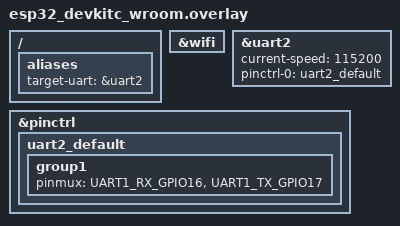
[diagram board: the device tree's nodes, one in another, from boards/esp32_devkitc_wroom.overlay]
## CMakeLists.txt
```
# Copyright (c) 2024 Common Ground Electronics
# SPDX-License-Identifier: Apache-2.0

cmake_minimum_required(VERSION 3.20.0)

find_package(Zephyr REQUIRED HINTS $ENV{ZEPHYR_BASE})
project(golioth-serial-logger)

target_sources(app PRIVATE src/main.c)
target_sources(app PRIVATE src/serial_listener.c)
target_sources(app PRIVATE src/logger.c)
```

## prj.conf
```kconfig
# Copyright (c) 2022-2023 Golioth, Inc.
# Copyright (c) 2024 Common Ground Electronics
# SPDX-License-Identifier: Apache-2.0

# Enable Golioth Firmware SDK
CONFIG_GOLIOTH_FIRMWARE_SDK=y

# Golioth services used in this app
CONFIG_GOLIOTH_FW_UPDATE=y
CONFIG_LOG_BACKEND_GOLIOTH=y

# Enable common sample library
CONFIG_GOLIOTH_SAMPLE_COMMON=y
CONFIG_GOLIOTH_SAMPLE_HARDCODED_CREDENTIALS=n

# Application
CONFIG_MAIN_STACK_SIZE=2048
CONFIG_SYSTEM_WORKQUEUE_STACK_SIZE=2048

# Flash memory (etc.) for firmware upgrade
CONFIG_FLASH=y
CONFIG_FLASH_MAP=y
CONFIG_NVS=y
CONFIG_STREAM_FLASH=y
CONFIG_IMG_MANAGER=y
CONFIG_IMG_ERASE_PROGRESSIVELY=y

# The rest of the runtime credentials config
CONFIG_SETTINGS=y
CONFIG_SETTINGS_RUNTIME=y
CONFIG_GOLIOTH_SAMPLE_PSK_SETTINGS=y
CONFIG_GOLIOTH_SAMPLE_SETTINGS_AUTOLOAD=y
CONFIG_GOLIOTH_SAMPLE_SETTINGS_SHELL=y

# Enable MCUboot
# CONFIG_BOOTLOADER_MCUBOOT=y

# Firmware version used in DFU process
CONFIG_MCUBOOT_IMGTOOL_SIGN_VERSION="0.1.0"
```

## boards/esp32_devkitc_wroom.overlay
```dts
/*
 * Copyright (c) 2024 Common Ground Electronics
 *
 * SPDX-License-Identifier: Apache-2.0
 */

/ {
	aliases {
		target-uart = &uart2;
	};
};

&wifi {
	status = "okay";
};

&uart2 {
	status = "okay";
	current-speed = <115200>;
	pinctrl-0 = <&uart2_default>;
	pinctrl-names = "default";
};

&pinctrl {
	uart2_default: uart2_default {
		group1 {
			pinmux = <UART1_RX_GPIO16>, <UART1_TX_GPIO17>;
		};
	};
};
```

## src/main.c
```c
/*
 * Copyright (c) 2024 Common Ground Electronics
 *
 * SPDX-License-Identifier: Apache-2.0
 */

#include <zephyr/kernel.h>
#include <zephyr/logging/log.h>
#include <golioth/client.h>
#include <samples/common/net_connect.h>
#include <samples/common/sample_credentials.h>

#include "serial_listener.h"
#include "logger.h"

LOG_MODULE_REGISTER(main, LOG_LEVEL_INF);

struct golioth_client *client;

static void on_client_event(struct golioth_client *client, enum golioth_client_event event,
			    void *arg)
{
	switch (event) {
	case GOLIOTH_CLIENT_EVENT_CONNECTED:
		LOG_INF("Golioth client connected");
		break;
	case GOLIOTH_CLIENT_EVENT_DISCONNECTED:
		LOG_INF("Golioth client disconnected");
		break;
	}
}

int main(void)
{
	int ret;
	char msg[LOG_MSG_SIZE];

	LOG_INF("Starting Golioth Serial Logger App");

	/* Initialize the serial listener */
	if (serial_listener_init()) {
		return 0;
	}

	/* Connect to WiFi */
	net_connect();

	/* Initialize the Golioth client */
	const struct golioth_client_config *client_config = golioth_sample_credentials_get();
	client = golioth_client_create(client_config);
	golioth_client_register_event_callback(client, on_client_event, NULL);

	/* Process any log messages in the queue */
	LOG_MODULE_DECLARE(u, LOG_LEVEL_INF);
	while (k_msgq_get(&uart_msgq, &msg, K_FOREVER) == 0) {
		/* Wait forever for the Golioth client to be connected */
		golioth_client_wait_for_connect(client, -1);

		// send out
		logger_log(msg);
	}

	return 0;
}
```

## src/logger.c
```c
#include <zephyr/kernel.h>
#include <zephyr/logging/log.h>

LOG_MODULE_REGISTER(l, LOG_LEVEL_INF);

void logger_log(const char * msg)
{
	// just print
	// printk("%s\n", msg);

	/* The Golioth logging backend will send this message to the Golioth cloud */
	LOG_INF("%s", msg);
}
```

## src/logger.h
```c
void logger_log(const char * msg);
```

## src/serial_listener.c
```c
/*
 * Copyright (c) 2022 Libre Solar Technologies GmbH
 * Copyright (c) 2024 Common Ground Electronics
 *
 * SPDX-License-Identifier: Apache-2.0
 */

#include <zephyr/kernel.h>
#include <zephyr/device.h>
#include <zephyr/drivers/uart.h>
#include <zephyr/logging/log.h>

#include "serial_listener.h"

#define UART_DEVICE_NODE DT_ALIAS(target_uart)
static const struct device *const uart_dev = DEVICE_DT_GET(UART_DEVICE_NODE);

LOG_MODULE_REGISTER(serial_listener, LOG_LEVEL_DBG);

/* queue to store log messages */
// #define LOG_MSG_QUEUE_SIZE 100
#define LOG_MSG_QUEUE_SIZE 50
K_MSGQ_DEFINE(uart_msgq, LOG_MSG_SIZE, LOG_MSG_QUEUE_SIZE, 1);

/* receive buffer used in UART ISR callback */
static char rx_buf[LOG_MSG_SIZE];
static int rx_buf_pos;

static void flush()
{
	/* terminate string */
	rx_buf[rx_buf_pos] = '\0';

	/* if queue is full, message is silently dropped */
	k_msgq_put(&uart_msgq, &rx_buf, K_NO_WAIT);

	/* reset the buffer (it was copied to the msgq) */
	rx_buf_pos = 0;
}

/*
 * Read characters from UART until line end is detected. Afterwards push the
 * data to the message queue.
 */
void serial_cb(const struct device *dev, void *user_data)
{
	uint8_t c;

	if (!uart_irq_update(uart_dev)) {
		return;
	}

	if (!uart_irq_rx_ready(uart_dev)) {
		return;
	}

	/* read until FIFO empty */
	while (uart_fifo_read(uart_dev, &c, 1) == 1) {
		if (rx_buf_pos == (sizeof(rx_buf) - 1)) { // did we fill the buffer?
			flush();
		}
		if ((c == '\n' || c == '\r')) { // if new line
			if (rx_buf_pos > 0) { // and not empty line, then
				flush();
			}
		} else if (rx_buf_pos < (sizeof(rx_buf) - 1)) { // not a new line character
			rx_buf[rx_buf_pos++] = c;
		}
	}
}

int serial_listener_init(void)
{
	int ret;

	/* Make sure the UART device exists and is ready */
	if (!device_is_ready(uart_dev)) {
		printk("UART device is not ready!\n");
		return -ENODEV;
	}

	/* Configure UART interrupt and callback to receive data */
	ret = uart_irq_callback_user_data_set(uart_dev, serial_cb, NULL);
	if (ret < 0) {
		if (ret == -ENOTSUP) {
			printk("Interrupt-driven UART API support not enabled\n");
		} else if (ret == -ENOSYS) {
			printk("UART device does not support interrupt-driven API\n");
		} else {
			printk("Error setting UART callback: %d\n", ret);
		}
		return ret;
	}
	uart_irq_rx_enable(uart_dev);

	return 0;
}
```

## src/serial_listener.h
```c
/*
 * Copyright (c) 2024 Common Ground Electronics
 *
 * SPDX-License-Identifier: Apache-2.0
 */

// #define LOG_MSG_SIZE 256
#define LOG_MSG_SIZE 1024

extern struct k_msgq uart_msgq;

int serial_listener_init(void);
```
